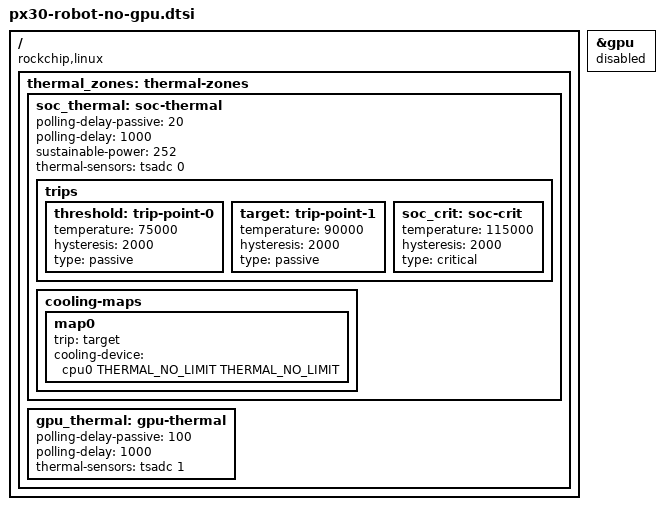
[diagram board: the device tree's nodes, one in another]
// SPDX-License-Identifier: (GPL-2.0+ OR MIT)
/*
 * Copyright (c) 2019 Fuzhou Rockchip Electronics Co., Ltd
 */
#include "px30-robot.dtsi"

/ {
	compatible = "rockchip,linux", "rockchip,px30-robot-no-gpu";

	/* Remove gpu thermal and gpu cooling map */
	/delete-node/ thermal-zones;

	thermal_zones: thermal-zones {
		soc_thermal: soc-thermal {
			polling-delay-passive = <20>;
			polling-delay = <1000>;
			sustainable-power = <252>;

			thermal-sensors = <&tsadc 0>;
			trips {
				threshold: trip-point-0 {
					temperature = <75000>;
					hysteresis = <2000>;
					type = "passive";
				};
				target: trip-point-1 {
					temperature = <90000>;
					hysteresis = <2000>;
					type = "passive";
				};
				soc_crit: soc-crit {
					temperature = <115000>;
					hysteresis = <2000>;
					type = "critical";
				};
			};

			cooling-maps {
				map0 {
					trip = <&target>;
					cooling-device = <&cpu0 THERMAL_NO_LIMIT THERMAL_NO_LIMIT>;
				};
			};
		};

		gpu_thermal: gpu-thermal {
			polling-delay-passive = <100>; /* milliseconds */
			polling-delay = <1000>; /* milliseconds */

			thermal-sensors = <&tsadc 1>;
		};
	};
};

&gpu {
	status = "disabled";
};
